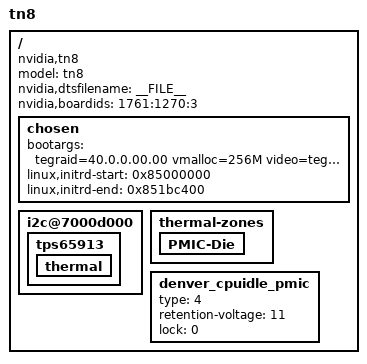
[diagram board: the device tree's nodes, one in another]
/dts-v1/;

#include "tegra132-tn8.dtsi"
#include "tegra124-platforms/tegra124-tn8-power-tree-e1936-1000-a00.dtsi"
#include "tegra124-platforms/tegra124-tn8-sensor-p1761-1270-a03.dtsi"
#include "tegra124-platforms/tegra124-tn8-pinmux-p1761-1470-a00.dtsi"
#include "tegra124-platforms/tegra124-tn8-gpio-p1761-1470-a00.dtsi"
#include "tegra132-platforms/tegra132-tn8-keys-p1761-1270-a03.dtsi"
#include "tegra132-platforms/tegra132-tn8-emc-p1761-1270-a03.dtsi"
#include "tegra124-platforms/tegra124-tn8-powermon-p1761-a02.dtsi"
#include "tegra132-tn8-dfll.dtsi"
#include "tegra124-platforms/tegra124-tn8-camera-p1761-1270-a03.dtsi"
#include "tegra124-platforms/tegra124-tn8-thermal-zone-p1761-1270-a00.dtsi"

/ {
	model = "tn8";
	compatible = "nvidia,tn8", "nvidia,tegra132";
	nvidia,dtsfilename = __FILE__;
	nvidia,boardids = "1761:1270:3";
	#address-cells = <2>;
	#size-cells = <2>;

	chosen {
		bootargs = "tegraid=40.0.0.00.00 vmalloc=256M video=tegrafb console=ttyS0,115200n8 earlyprintk";
		linux,initrd-start = <0x85000000>;
		linux,initrd-end = <0x851bc400>;
	};

	i2c@7000d000 {
		tps65913 {
			thermal {
				status = "okay";
			};
		};
	};

	thermal-zones {
	       PMIC-Die {
			status = "okay";
		};
	};

	denver_cpuidle_pmic {
		type = <4>; /* TI TPS65913 2.3 */
		retention-voltage = <11>; /* vret = .55V */
		lock = <0>;
       };
};

